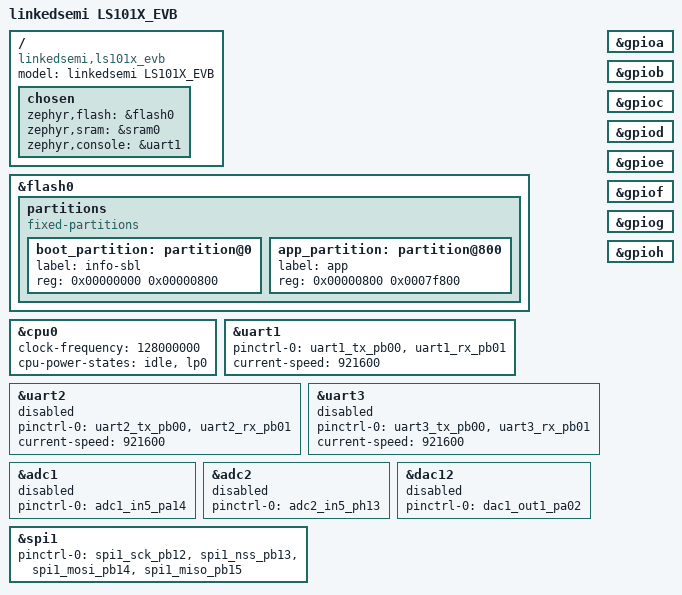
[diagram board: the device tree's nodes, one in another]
/*
 * Copyright (c) 2021, Teslabs Engineering S.L.
 * SPDX-License-Identifier: Apache-2.0
 */

// #include <gigadevice/gd32vf103Xb.dtsi>
// #include "gd32vf103v_eval-pinctrl.dtsi"
/dts-v1/;
#include <riscv/linkedsemi/ls101x.dtsi>
#include "ls101x_evb-pinctrl.dtsi"
#include <zephyr/dt-bindings/pinctrl/ls101x-pinctrl.h>
#include <zephyr/dt-bindings/input/input-event-codes.h>

/ {
	model = "linkedsemi LS101X_EVB";
	compatible = "linkedsemi,ls101x_evb";

	chosen {
		zephyr,flash = &flash0;
		zephyr,sram = &sram0;
		zephyr,console = &uart1;
	};
    // aliases {

	// };


};

&flash0 {

    /*
	* Flash base address is 0x8000000,
    * the following parts are all offset addresses.
	*/

	partitions {
		compatible = "fixed-partitions";
		#address-cells = <1>;
		#size-cells = <1>;

		boot_partition: partition@0 {
			label = "info-sbl";
			reg = <0x00000000 0x00000800>;
		};
	
        app_partition: partition@800 {
			label = "app";
			reg = <0x00000800 0x0007f800>;
		};

		/*
		 * The flash starting at 0x1807C000 and ending at
		 * 0x1807FFFF is reserved for use by the application.
		 */

		/*
		 * Storage partition will be used by FCB/LittleFS/NVS
		 * if enabled.
		 */
		// storage_partition: partition@7C000 {
		// 	label = "storage";
		// 	reg = <0x0007c000 0x00004000>;
		// };
	};
};

&cpu0 {
	clock-frequency = <128000000>;
	cpu-power-states = <&idle &lp0>;
};

&uart1 {
	status = "okay";
	pinctrl-0 = <&uart1_tx_pb00 &uart1_rx_pb01>;
	pinctrl-names = "default";
	current-speed = <921600>;
};
&uart2 {
	status = "disabled";
	pinctrl-0 = <&uart2_tx_pb00 &uart2_rx_pb01>;
	pinctrl-names = "default";
	current-speed = <921600>;
};
&uart3 {
	status = "disabled";
	pinctrl-0 = <&uart3_tx_pb00 &uart3_rx_pb01>;
	pinctrl-names = "default";
	current-speed = <921600>;
};

&adc1 {
	status = "disabled";
	pinctrl-0 = <&adc1_in5_pa14>;
	pinctrl-names = "default";
};

&adc2 {
	status = "disabled";
	pinctrl-0 = <&adc2_in5_ph13>;
	// pinctrl-0 = <&amic_pa00>;
	pinctrl-names = "default";
};

&dac12 {
	status = "disabled";
	pinctrl-0 = <&dac1_out1_pa02>;
	pinctrl-names = "default";
};

&spi1 {
	status = "okay";
	pinctrl-0 = <&spi1_sck_pb12  &spi1_nss_pb13
				 &spi1_mosi_pb14 &spi1_miso_pb15>;
	pinctrl-names = "default";

	// cs-gpios = <&gpiob 13 GPIO_ACTIVE_HIGH>;
};

&gpioa {
	status = "okay";
};

&gpiob {
	status = "okay";
};

&gpioc {
	status = "okay";
};

&gpiod {
	status = "okay";
};

&gpioe {
	status = "okay";
};

&gpiof {
	status = "okay";
};

&gpiog {
	status = "okay";
};

&gpioh {
	status = "okay";
};

